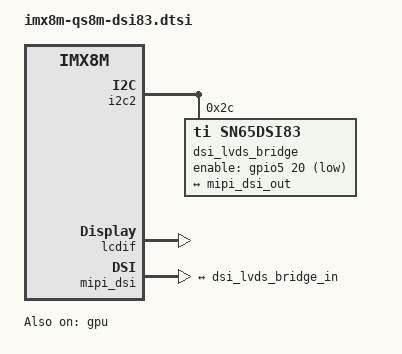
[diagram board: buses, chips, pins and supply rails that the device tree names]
// SPDX-License-Identifier: (GPL-2.0 OR MIT)
/*
 * Copyright (C) 2020 Markus Bauer <MB@KARO-electronics.de>
 *
 */

&gpu {
	status = "okay";
};

&i2c2 {
	dsi_lvds_bridge: sn65dsi84@2c {
		compatible = "ti,sn65dsi83";
		reg = <0x2c>;
		ti,dsi-lanes = <2>;
		ti,lvds-format = <2>;
		ti,lvds-bpp = <24>;
		ti,width-mm = <217>;
		ti,height-mm = <136>;
		enable-gpios = <&gpio5 20 GPIO_ACTIVE_LOW>;
		status = "okay";

		display-timings {
			lvds {
				clock-frequency = <62500000>;
				hactive = <1280>;
				vactive = <800>;
				hback-porch = <6>;
				hfront-porch = <5>;
				vback-porch = <2>;
				vfront-porch = <3>;
				hsync-len = <2>;
				vsync-len = <1>;
				hsync-active = <0>;
				vsync-active = <0>;
				de-active = <0>;
				pixelclk-active = <0>;
			};
		};

		port {
			dsi_lvds_bridge_in: endpoint {
				remote-endpoint = <&mipi_dsi_out>;
			};
		};
	};
};

&lcdif {
	status = "okay";
};

&mipi_dsi {
	status = "okay";

	port@1 {
		reg = <1>;

		mipi_dsi_out: endpoint {
			remote-endpoint = <&dsi_lvds_bridge_in>;
			attach-bridge;
		};
	};
};
